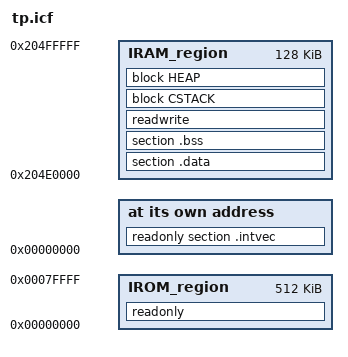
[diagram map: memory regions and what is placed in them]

define symbol __intvec_start__ = 0x00000000;
/*-Memory Regions-*/
define symbol __ICFEDIT_region_IROM1_start__ = 0x00000000;
define symbol __ICFEDIT_region_IROM1_end__   = 0x0007FFFF;

define symbol __ICFEDIT_region_IRAM1_start__ = 0x204E0000;
define symbol __ICFEDIT_region_IRAM1_end__   = 0x204FFFFF;

/*-Sizes-*/
define symbol __ICFEDIT_size_cstack__        = 0x400;
define symbol __ICFEDIT_size_heap__          = 0x800;


define memory mem with size = 4G;

define region IROM_region = mem:[from __ICFEDIT_region_IROM1_start__ to __ICFEDIT_region_IROM1_end__];

define region IRAM_region = mem:[from __ICFEDIT_region_IRAM1_start__ to __ICFEDIT_region_IRAM1_end__];

define block CSTACK        with alignment = 8, size = __ICFEDIT_size_cstack__        { };
define block HEAP          with alignment = 8, size = __ICFEDIT_size_heap__          { };

do not initialize  { section .noinit };
initialize by copy { readwrite };

place at address mem:__intvec_start__ { readonly section .intvec };

place in IROM_region  { readonly };

place in IRAM_region  { section .data, section .bss, readwrite, block CSTACK, block HEAP };
